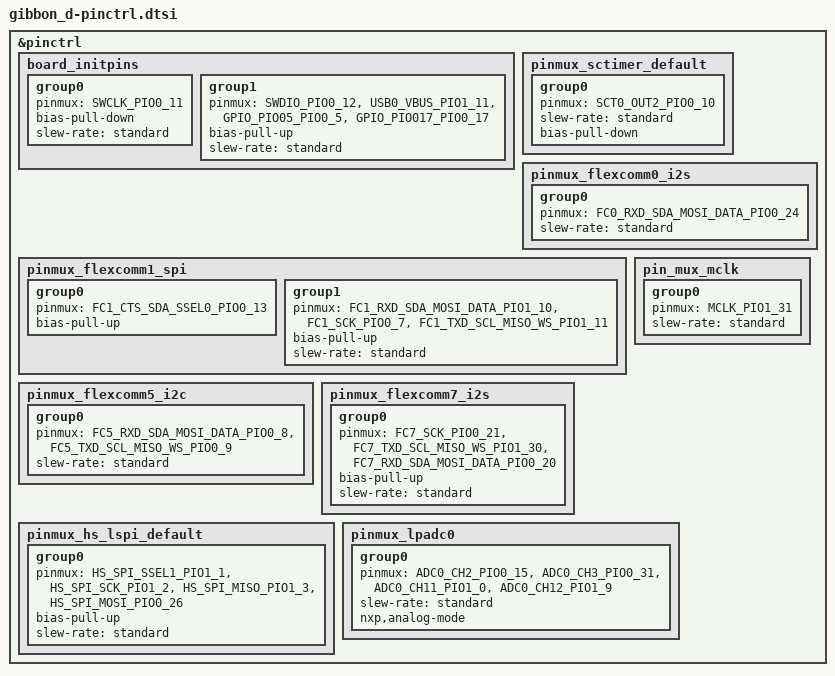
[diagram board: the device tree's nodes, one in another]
/*
 * NOTE: File generated by lpc_cfg_utils.py
 * from hello_world.mex
 *
 * 
 */

#include <nxp/lpc/LPC55S69JEV98-pinctrl.h>

&pinctrl {
	/* Configures pin routing and optionally pin electrical features. */
	board_initpins: board_initpins {
		group0 {
			pinmux = <SWCLK_PIO0_11>;
			bias-pull-down;
			slew-rate = "standard";
		};
		group1 {
			pinmux = <SWDIO_PIO0_12>,
				<USB0_VBUS_PIO1_11>,
				<GPIO_PIO05_PIO0_5>,
				<GPIO_PIO017_PIO0_17>;
			bias-pull-up;
			slew-rate = "standard";
		};
	};

	pinmux_sctimer_default: pinmux_sctimer_default {
		group0 {
			pinmux =  <SCT0_OUT2_PIO0_10>;
			slew-rate = "standard";
			bias-pull-down;
		};
	};

	pinmux_flexcomm0_i2s: pinmux_flexcomm0_i2s {
		group0 {
			pinmux = <FC0_RXD_SDA_MOSI_DATA_PIO0_24>;
			slew-rate = "standard";
		};
	};

	pinmux_flexcomm1_spi: pinmux_flexcomm1_spi{
		group0 {
				pinmux = <FC1_CTS_SDA_SSEL0_PIO0_13>;
				bias-pull-up;
		};
		group1 {
			pinmux = <FC1_RXD_SDA_MOSI_DATA_PIO1_10>,
					 <FC1_SCK_PIO0_7>,
					 <FC1_TXD_SCL_MISO_WS_PIO1_11>;
			bias-pull-up;
			slew-rate = "standard";
		};
	};

	pinmux_flexcomm5_i2c: pinmux_flexcomm5_i2c {
		group0 {
			pinmux = <FC5_RXD_SDA_MOSI_DATA_PIO0_8>,
					 <FC5_TXD_SCL_MISO_WS_PIO0_9>;
			slew-rate = "standard";
		};
	};


	pinmux_flexcomm7_i2s: pinmux_flexcomm7_i2s {
		group0 {
			pinmux =<FC7_SCK_PIO0_21>,
					<FC7_TXD_SCL_MISO_WS_PIO1_30>,
					<FC7_RXD_SDA_MOSI_DATA_PIO0_20>;
			bias-pull-up;
			slew-rate = "standard";
		};
	};


	pinmux_hs_lspi_default: pinmux_hs_lspi_default {
		group0 {
			pinmux = <HS_SPI_SSEL1_PIO1_1>,
				<HS_SPI_SCK_PIO1_2>,
				<HS_SPI_MISO_PIO1_3>,
				<HS_SPI_MOSI_PIO0_26>;
			bias-pull-up;
			slew-rate = "standard";
		};
	};

	pin_mux_mclk: pin_mux_mclk {
		group0 {
			pinmux = <MCLK_PIO1_31>;
			slew-rate = "standard";
		};
	};

	pinmux_lpadc0: pinmux_lpadc0 {
		group0 {
			pinmux = <ADC0_CH2_PIO0_15>,
					 <ADC0_CH3_PIO0_31>,
					 <ADC0_CH11_PIO1_0>,
					 <ADC0_CH12_PIO1_9>;
			slew-rate = "standard";
			nxp,analog-mode;
		};
	};
};
